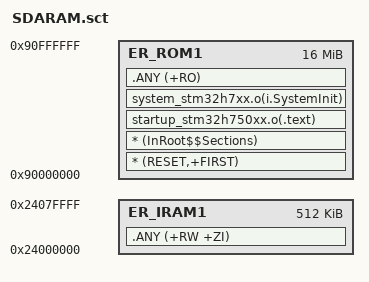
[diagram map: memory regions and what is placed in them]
; *************************************************************
; *** Scatter-Loading Description File generated by uVision ***
; *************************************************************


LR_ROM1 0x90000000 0x01000000 {    ; load region size_region
   ER_ROM1  0x90000000 0x01000000  {  ; load address = execution address
   * (RESET,+FIRST)
   * (InRoot$$Sections)
   startup_stm32h750xx.o(.text)
   system_stm32h7xx.o(i.SystemInit)
    .ANY (+RO)
  }
   ER_IRAM1 0x24000000 0x00080000 { ; RW data
   .ANY (+RW +ZI)
  }

} 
